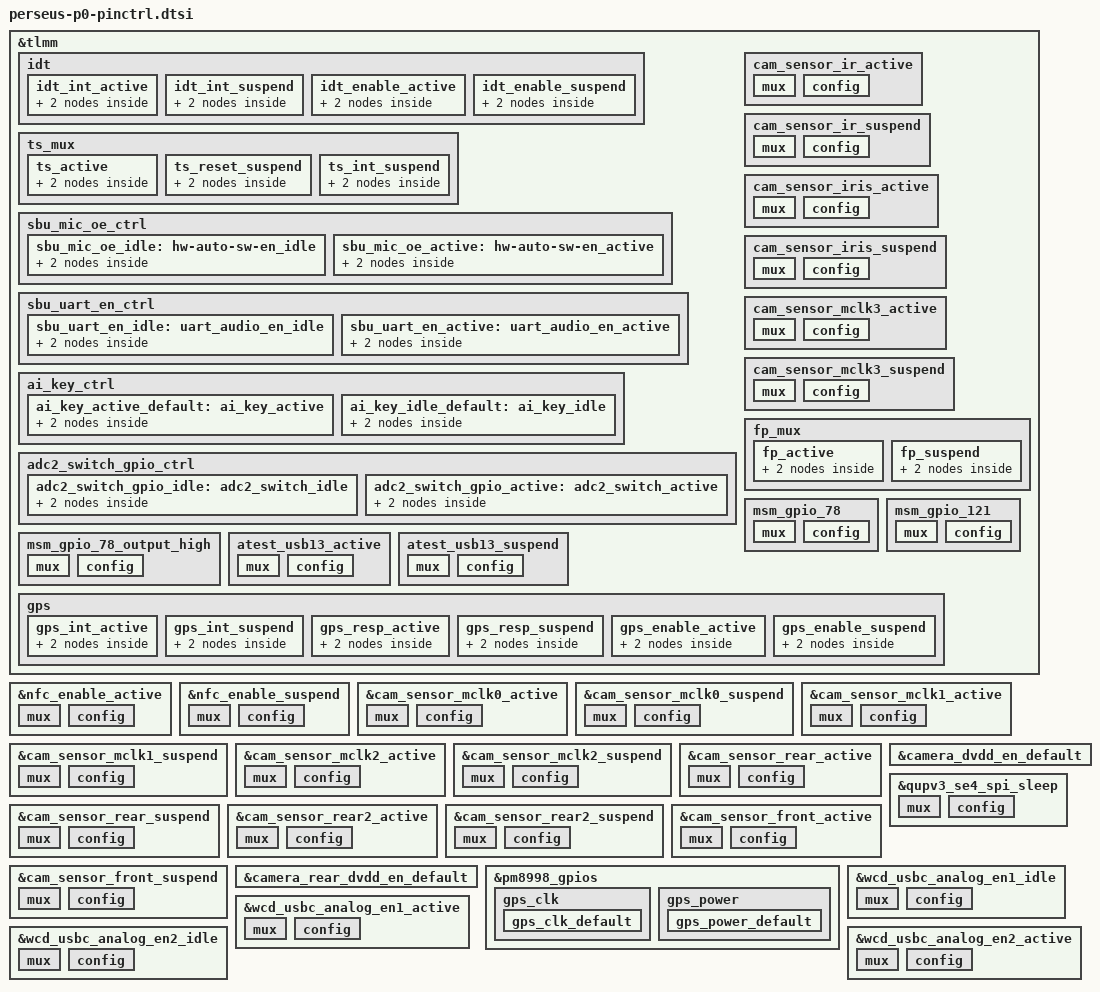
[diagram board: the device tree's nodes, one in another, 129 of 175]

/* Copyright (c) 2016-2017, The Linux Foundation. All rights reserved.
 * Copyright (C) 2019 XiaoMi, Inc.
 *
 * This program is free software; you can redistribute it and/or modify
 * it under the terms of the GNU General Public License version 2 and
 * only version 2 as published by the Free Software Foundation.
 *
 * This program is distributed in the hope that it will be useful,
 * but WITHOUT ANY WARRANTY; without even the implied warranty of
 * MERCHANTABILITY or FITNESS FOR A PARTICULAR PURPOSE.  See the
 * GNU General Public License for more details.
 */

&tlmm {
	idt {
		idt_int_active: idt_int_active {
			/* active state */
			mux {
				/* GPIO 62 idt Read Interrupt */
				pins = "gpio62";
				function = "gpio";
			};

			config {
				pins = "gpio62";
				drive-strength = <2>; /* 2 MA */
				bias-pull-up;
				input-enable;
			};
		};

		idt_int_suspend: idt_int_suspend {
			/* sleep state */
			mux {
				/* GPIO 62 idt Read Interrupt */
				pins = "gpio62";
				function = "gpio";
			};

			config {
				pins = "gpio62";
				drive-strength = <2>; /* 2 MA */
				bias-pull-up;
				input-enable;
			};
		};

		idt_enable_active: idt_enable_active {
			/* active state */
			mux {
				/* GPIO 93 idt enable pin */
				pins = "gpio93";
				function = "gpio";
			};

			config {
				pins = "gpio93";
				drive-strength = <2>;
				bias-disable;
				bias-pull-down;
				output-low;
			};
		};

		idt_enable_suspend: idt_enable_suspend {
			/* sleep state */
			mux {
				/* GPIO 93 idt enable pin */
				pins = "gpio93";
				function = "gpio";
			};

			config {
				pins = "gpio93";
				drive-strength = <2>;
				bias-pull-up;
			};
		};
	};

	ts_mux {
		ts_active: ts_active {
			mux {
				pins = "gpio31", "gpio32";
				function = "gpio";
			};

			config {
				pins = "gpio31", "gpio32";
				drive-strength = <16>;
				bias-pull-up;
			};
		};

		ts_reset_suspend: ts_reset_suspend {
			mux {
				pins = "gpio32";
				function = "gpio";
			};

			config {
				pins = "gpio32";
				drive-strength = <2>;
				bias-disable;
			};
		};

		ts_int_suspend: ts_int_suspend {
			mux {
				pins = "gpio31";
				function = "gpio";
			};

			config {
				pins = "gpio31";
				drive-strength = <2>;
				bias-disable;
			};
		};
	};

	sbu_mic_oe_ctrl {
		sbu_mic_oe_idle: hw-auto-sw-en_idle {
			mux {
				pins = "gpio43";
				function = "gpio";
			};
			config {
				pins = "gpio43";
				drive-strength = <2>;
				bias-pull-down;
				output-low;
			};
		};

		sbu_mic_oe_active: hw-auto-sw-en_active {
			mux {
				pins = "gpio43";
				function = "gpio";
			};
			config {
				pins = "gpio43";
				drive-strength = <2>;
				bias-disable;
				output-high;
			};
		};
	};

	sbu_uart_en_ctrl {
		sbu_uart_en_idle: uart_audio_en_idle {
			mux {
				pins = "gpio51";
				function = "gpio";
			};
			config {
				pins = "gpio51";
				drive-strength = <2>;
				bias-pull-down;
				output-low;
			};
		};

		sbu_uart_en_active: uart_audio_en_active {
			mux {
				pins = "gpio51";
				function = "gpio";
			};
			config {
				pins = "gpio51";
				drive-strength = <2>;
				bias-disable;
				output-high;
			};
		};
	};

	ai_key_ctrl {
		ai_key_active_default: ai_key_active {
			mux {
				pins = "gpio44";
				function = "gpio";
			};
			config {
				pins = "gpio44";
				drive-strength = <2>;
				bias-pull-up;
				input-enable;
			};

		};

		ai_key_idle_default: ai_key_idle {
			mux {
				pins = "gpio44";
				function = "gpio";
			};
			config {
				pins = "gpio44";
				drive-strength = <2>;
				bias-pull-up;
				input-enable;
			};
		};
	};

	adc2_switch_gpio_ctrl {
		adc2_switch_gpio_idle: adc2_switch_idle {
			mux {
				pins = "gpio28";
				function = "gpio";
			};
			config {
				pins = "gpio28";
				drive-strength = <2>;
				bias-pull-down;
				output-low;
			};
		};

		adc2_switch_gpio_active: adc2_switch_active {
			mux {
				pins = "gpio28";
				function = "gpio";
			};
			config {
				pins = "gpio28";
				drive-strength = <2>;
				bias-disable;
				output-high;
			};
		};
	};

	cam_sensor_ir_active: cam_sensor_ir_active {
		/* RESET  AVDD_LDO*/
		mux {
			pins = "gpio25", "gpio27";
			function = "gpio";
		};

		config {
			pins = "gpio25", "gpio27";
			bias-disable; /* No PULL */
			drive-strength = <2>; /* 2 MA */
		};
	};

	cam_sensor_ir_suspend: cam_sensor_ir_suspend {
		/* RESET */
		mux {
			pins = "gpio25", "gpio27";
			function = "gpio";
		};

		config {
			pins = "gpio25", "gpio27";
			bias-pull-down; /* PULL DOWN */
			drive-strength = <2>; /* 2 MA */
			output-low;
		};
	};

	cam_sensor_iris_active: cam_sensor_iris_active {
		/* RESET  AVDD_LDO*/
		mux {
			pins = "gpio9", "gpio8";
			function = "gpio";
		};

		config {
			pins = "gpio9", "gpio8";
			bias-disable; /* No PULL */
			drive-strength = <2>; /* 2 MA */
		};
	};

	cam_sensor_iris_suspend: cam_sensor_iris_suspend {
		/* RESET */
		mux {
			pins = "gpio9";
			function = "gpio";
		};

		config {
			pins = "gpio9";
			bias-disable; /* No PULL */
			drive-strength = <2>; /* 2 MA */
			output-low;
		};
	};

	cam_sensor_mclk3_active: cam_sensor_mclk3_active {
		/* MCLK3 */
		mux {
			/* CLK, DATA */
			pins = "gpio16";
			function = "cam_mclk";
		};

		config {
			pins = "gpio16";
			bias-disable; /* No PULL */
			drive-strength = <4>; /* 2 MA */
		};
	};

	cam_sensor_mclk3_suspend: cam_sensor_mclk3_suspend {
		/* MCLK3 */
		mux {
			/* CLK, DATA */
			pins = "gpio16";
			function = "cam_mclk";
		};

		config {
			pins = "gpio16";
			bias-pull-down; /* PULL DOWN */
			drive-strength = <4>; /* 2 MA */
			output-low;
		};
	};

	fp_mux {
		fp_active: fp_active {
			mux {
				pins = "gpio121";
				function = "gpio";
			};
			config {
				pins = "gpio121";
				drive-strength = <8>;
				bias-disable;
			};
		};

		fp_suspend: fp_suspend {
			mux {
				pins = "gpio121";
				function = "gpio";
			};
			config {
				pins = "gpio121";
				drive-strength = <2>;
				bias-disable;
			};
		};
	};
	/* GPIO_78 : FP_RESET_N */
	msm_gpio_78: msm_gpio_78 {
		mux {
			 pins = "gpio78";
			 function = "gpio";
		};

		config {
			pins = "gpio78";
			drive-strength = <2>;
			bias-disable;
			output-low;
		};
	};

	/* GPIO_78 : FP_RESET_N, state device active*/
	msm_gpio_78_output_high: msm_gpio_78_output_high {
		mux {
			pins = "gpio78";
			function = "gpio";
		};

		config {
			pins = "gpio78";
			drive-strength = <2>;
			bias-disable;
			output-high;
		};
	};

	/* GPIO_121 : FP_INT_N */
	msm_gpio_121: msm_gpio_121 {
		mux {
			pins = "gpio121";
			function = "gpio";
		};

		config {
			pins = "gpio121";
			drive-strength = <2>;
			bias-pull-down;
		};
	};
	atest_usb13_active: atest_usb13_active {
		mux {
			pins = "gpio8";
			function = "gpio";
		};
		config {
			pins = "gpio8";
			drive-strength = <12>;
			bias-pull-up;
		};
	};

	atest_usb13_suspend: atest_usb13_suspend {
		mux {
			pins = "gpio8";
			function = "gpio";
		};
		config {
			pins = "gpio8";
			bias-pull-down;
			drive-strength = <2>;
		};
	};
};

&nfc_enable_active {
	/* active state */
	mux {
		/* 128: NFC ENABLE 116:ESE Enable */
		pins = "gpio128", "gpio88", "gpio116";
		function = "gpio";
	};

	config {
		pins = "gpio128", "gpio88", "gpio116";
		drive-strength = <2>; /* 2 MA */
		bias-pull-up;
	};
};

&nfc_enable_suspend {
	/* sleep state */
	mux {
		/* 128: NFC ENABLE 116:ESE Enable */
		pins = "gpio128", "gpio88", "gpio116";
		function = "gpio";
	};

	config {
		pins = "gpio128", "gpio88", "gpio116";
		drive-strength = <2>; /* 2 MA */
		bias-disable;
	};
};

&cam_sensor_mclk0_active {
	/* MCLK0 */
	mux {
		pins = "gpio13";
		function = "cam_mclk";
	};

	config {
		pins = "gpio13";
		bias-disable; /* No PULL */
		drive-strength = <4>; /* 2 MA */
	};
};

&cam_sensor_mclk0_suspend {
	/* MCLK0 */
	mux {
		pins = "gpio13";
		function = "cam_mclk";
	};

	config {
		pins = "gpio13";
		bias-pull-down; /* PULL DOWN */
		drive-strength = <4>; /* 2 MA */
	};
};

&cam_sensor_mclk1_active {
	/* MCLK1 */
	mux {
		pins = "gpio14";
		function = "cam_mclk";
	};

	config {
		pins = "gpio14";
				bias-disable; /* No PULL */
		drive-strength = <4>; /* 2 MA */
	};
};

&cam_sensor_mclk1_suspend {
	/* MCLK1 */
	mux {
		pins = "gpio14";
		function = "cam_mclk";
	};

	config {
		pins = "gpio14";
		bias-pull-down; /* PULL DOWN */
		drive-strength = <4>; /* 2 MA */
		output-low;
	};
};

&cam_sensor_mclk2_active {
	/* MCLK1 */
	mux {
	/* CLK, DATA */
		pins = "gpio15";
		function = "cam_mclk";
	};

	config {
		pins = "gpio15";
		bias-disable; /* No PULL */
		drive-strength = <4>; /* 2 MA */
	};
};

&cam_sensor_mclk2_suspend {
	/* MCLK1 */
	mux {
		/* CLK, DATA */
		pins = "gpio15";
		function = "cam_mclk";
	};

	config {
		pins = "gpio15";
		bias-pull-down; /* PULL DOWN */
		drive-strength = <4>; /* 2 MA */
	};
};

&cam_sensor_mclk3_active {
	/* MCLK3 */
	mux {
		pins = "gpio16";
		function = "cam_mclk";
	};

	config {
		pins = "gpio16";
		bias-disable; /* No PULL */
		drive-strength = <4>; /* 2 MA */
	};
};

&cam_sensor_mclk3_suspend {
	/* MCLK3 */
	mux {
		pins = "gpio16";
		function = "cam_mclk";
	};

	config {
		pins = "gpio16";
		bias-pull-down; /* PULL DOWN */
		drive-strength = <4>; /* 2 MA */
	};
};

&cam_sensor_rear_active {
	/* RESET, AVDD LDO */
	mux {
		pins = "gpio24","gpio40","gpio11","gpio102";
		function = "gpio";
	};

	config {
		pins = "gpio24","gpio40","gpio11","gpio102";
				bias-disable; /* No PULL */
		drive-strength = <2>; /* 2 MA */
	};
};

&cam_sensor_rear_suspend {
	/* RESET, AVDD LDO */
	mux {
		pins = "gpio24","gpio40","gpio11","gpio102";
		function = "gpio";
	};

	config {
		pins = "gpio24","gpio40","gpio11","gpio102";
		bias-pull-down; /* PULL DOWN */
		drive-strength = <2>; /* 2 MA */
		output-low;
	};
};

&cam_sensor_rear2_active {
	/* RESET, STANDBY */
	mux {
		pins = "gpio37","gpio39","gpio23","gpio36";
		function = "gpio";
	};

	config {
		pins = "gpio37","gpio39","gpio23","gpio36";
		bias-disable; /* No PULL */
		drive-strength = <2>; /* 2 MA */
	};
};

&cam_sensor_rear2_suspend {
	/* RESET, STANDBY */
	mux {
		pins = "gpio37","gpio39","gpio23","gpio36";
		function = "gpio";
	};
	config {
		pins = "gpio37","gpio39","gpio23","gpio36";
		bias-pull-down; /* PULL DOWN */
		drive-strength = <2>; /* 2 MA */
		output-low;
	};
};

&cam_sensor_front_active {
	/* RESET  AVDD_LDO*/
	mux {
		pins = "gpio104","gpio9","gpio29";
		function = "gpio";
	};

	config {
		pins = "gpio104","gpio9","gpio29";
		bias-disable; /* No PULL */
		drive-strength = <2>; /* 2 MA */
	};
};

&cam_sensor_front_suspend {
	/* RESET */
	mux {
		pins = "gpio104","gpio9","gpio29";
		function = "gpio";
	};

	config {
		pins = "gpio104","gpio9","gpio29";
		bias-pull-down; /* PULL DOWN */
		drive-strength = <2>; /* 2 MA */
	};
};

&cam_sensor_ir_active {
	/* RESET  AVDD_LDO*/
	mux {
		pins = "gpio25", "gpio27";
		function = "gpio";
	};

	config {
		pins = "gpio25", "gpio27";
		bias-disable; /* No PULL */
		drive-strength = <2>; /* 2 MA */
	};
};

&cam_sensor_ir_suspend {
	/* RESET */
	mux {
		pins = "gpio25", "gpio27";
		function = "gpio";
	};

	config {
		pins = "gpio25", "gpio27";
		bias-pull-down; /* PULL DOWN */
		drive-strength = <2>; /* 2 MA */
	};
};

&camera_dvdd_en_default {
	pins = "gpio9";
	function = "normal";
	power-source = <0>;
	output-low;
};

&camera_rear_dvdd_en_default {
	pins = "gpio11";
	function = "normal";
	power-source = <0>;
	output-low;
};

&cam_sensor_iris_active {
	/* RESET  AVDD_LDO*/
	mux {
		pins = "gpio25", "gpio27";
		function = "gpio";
	};

	config {
		pins = "gpio25", "gpio27";
		bias-disable; /* No PULL */
		drive-strength = <2>; /* 2 MA */
	};
};

&cam_sensor_iris_suspend {
	/* RESET */
	mux {
		pins = "gpio25", "gpio27";
		function = "gpio";
	};

	config {
		pins = "gpio25", "gpio27";
		bias-pull-down; /* PULL DOWN */
		drive-strength = <2>; /* 2 MA */
	};
};


&qupv3_se4_spi_sleep {
	mux {
		pins = "gpio89", "gpio90", "gpio91",
			"gpio92";
		function = "gpio";
	};

	config {
		pins = "gpio89", "gpio90", "gpio91",
			"gpio92";
		drive-strength = <6>;
		bias-disable;
		output-high;
	};
};


&pm8998_gpios {
	gps_clk {
		gps_clk_default: gps_clk_default {
			pins = "gpio16";
			function = "func1";
			bias-disable;
			output-low;
			input-disable;
			power-source = <0>;
		};

	};
	gps_power {
		gps_power_default:gps_power_default {
			pins = "gpio19"; /* GPIO 19 */
			function = "normal"; /* normal output */
			power-source = <1>; /* VIN0 */
			output-high; /* digital output, no invert */
			input-disable; /* prevent GPIO from being set to DIO */
		};
	};
};

&tlmm {
	gps {
		gps_int_active: gps_int_active {
		/* active state */
			mux {
				/* GPIO 129 gps Read Interrupt */
				pins = "gpio129";
				function = "gpio";
			};

			config {
				pins = "gpio129";
				drive-strength = <2>; /* 2 MA */
				input-enable;
			};
		};

		gps_int_suspend: gps_int_suspend {
		/* sleep state */
			mux {
				/* GPIO 129 gps Read Interrupt */
				pins = "gpio129";
				function = "gpio";
			};

			config {
				pins = "gpio129";
				drive-strength = <2>; /* 2 MA */
				input-enable;
			};
		};
		gps_resp_active: gps_resp_active {
			/* active state */
			mux {
				/* 132: gps mcu rdy */
				pins = "gpio132";
				function = "gpio";
			};

			config {
				pins = "gpio132";
				drive-strength = <2>; /* 2 MA */
				input-enable;
				bias-disable;
				};
		};

		gps_resp_suspend: gps_resp_suspend {
			/* sleep state */
			mux {
				/* GPIO 132 gps mcu ready */
				pins = "gpio132";
				function = "gpio";
			};

			config {
				pins = "gpio132";
				drive-strength = <2>; /* 2 MA */
				input-enable;
				bias-disable;
			};
		};
		gps_enable_active: gps_enable_active {
			/* active state */
			mux {
				/* 133:gps nstandby 143:gps mcu req*/
				pins = "gpio133", "gpio143";
				function = "gpio";
			};

			config {
				pins = "gpio133", "gpio143";
				drive-strength = <2>; /* 2 MA */
				output-low;
				};
		};

		gps_enable_suspend: gps_enable_suspend {
			/* sleep state */
			mux {
				/* 133:gps nstandby 143:gps mcu req */
				pins = "gpio133", "gpio143";
				function = "gpio";
			};

			config {
				pins = "gpio133", "gpio143";
				drive-strength = <2>; /* 2 MA */
				output-low;
			};
		};
	};

};

&wcd_usbc_analog_en1_idle {
	mux {
		pins = "gpio119";
		function = "gpio";
	};
	config {
		pins = "gpio119";
		drive-strength = <2>;
		bias-pull-down;
		output-low;
	};
};
&wcd_usbc_analog_en1_active {
	mux {
		pins = "gpio119";
		function = "gpio";
	};
	config {
		pins = "gpio119";
		drive-strength = <2>;
		bias-disable;
		output-high;
	};
};
&wcd_usbc_analog_en2_idle {
	mux {
		pins = "gpio80";
		function = "gpio";
	};
	config {
		pins = "gpio80";
		drive-strength = <2>;
		bias-pull-down;
		output-low;
	};
};
&wcd_usbc_analog_en2_active {
	mux {
		pins = "gpio80";
		function = "gpio";
	};
	config {
		pins = "gpio80";
		drive-strength = <2>;
		bias-disable;
		output-high;
	};
};
